VERSION ""

NS_ :

BS_:

BU_: XXX

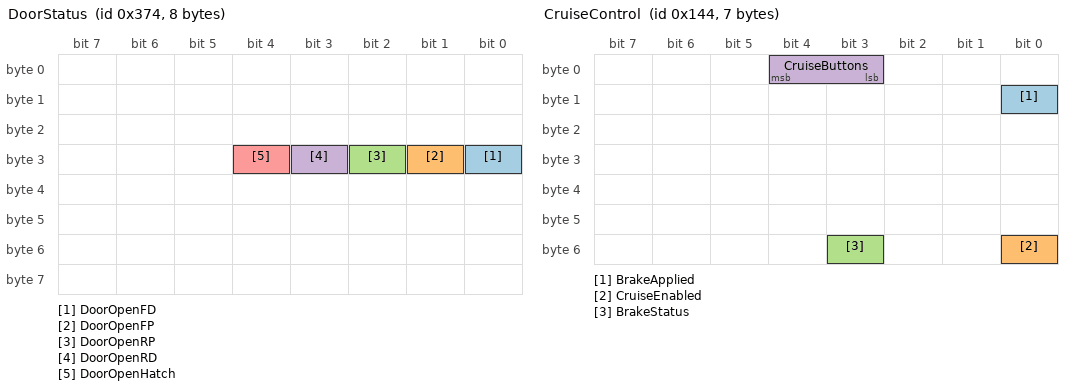
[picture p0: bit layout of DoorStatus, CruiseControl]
BO_ 884 DoorStatus: 8 XXX
 SG_ DoorOpenFD : 24|1@0+ (1,0) [0|1] "" XXX
 SG_ DoorOpenFP : 25|1@0+ (1,0) [0|1] "" XXX
 SG_ DoorOpenRP : 26|1@0+ (1,0) [0|1] "" XXX
 SG_ DoorOpenRD : 27|1@0+ (1,0) [0|1] "" XXX
 SG_ DoorOpenHatch : 28|1@0+ (1,0) [0|1] "" XXX

BO_ 324 CruiseControl: 7 XXX
 SG_ BrakeApplied : 8|1@0+ (1,0) [0|0] "" XXX
 SG_ CruiseEnabled : 48|1@0+ (1,0) [0|0] "" XXX
 SG_ BrakeStatus : 51|1@0+ (1,0) [0|0] "" XXX
 SG_ CruiseButtons : 4|2@0+ (1,0) [0|3] "" XXX

BO_ 320 Throttle: 8 XXX
 SG_ ThrottlePosition : 7|8@0+ (1,0) [0|255] "" XXX

BO_ 209 NEW_MSG_1: 8 XXX
 SG_ BrakePosition : 23|8@0+ (1,0) [0|255] "" XXX

BO_ 2 Steering: 8 XXX
 SG_ SteeringAngle : 7|16@0- (0.1,0) [-500|500] "degree" XXX

BO_ 642 NEW_MSG_2: 8 XXX
 SG_ TurnSignal : 45|2@0+ (1,0) [0|3] "" XXX

VAL_ 324 BrakeApplied 1 "On" 0 "Off" ;
VAL_ 324 CruiseEnabled 1 "On" 0 "Off" ;
VAL_ 324 BrakeStatus 1 "On" 0 "Off" ;
VAL_ 324 CruiseButtons 2 "Set" 1 "Resume" ;

VAL_ 624 TurnSignal 2 "Left" 1 "Right" ;

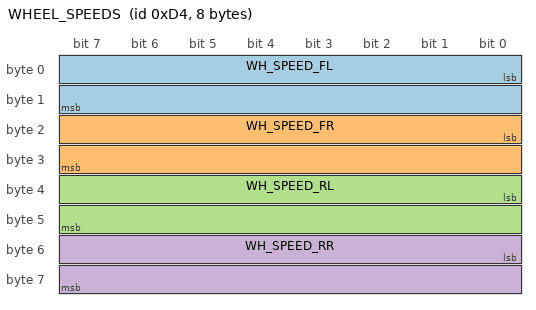
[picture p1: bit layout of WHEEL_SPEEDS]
BO_ 212 WHEEL_SPEEDS: 8 XXX
 SG_ WH_SPEED_FL : 0|16@1- (0.05625,0) [0|65535] "km/h" XXX
 SG_ WH_SPEED_FR : 16|16@1- (0.05625,0) [0|65535] "km/h" XXX
 SG_ WH_SPEED_RL : 32|16@1- (0.05625,0) [0|65535] "km/h" XXX
 SG_ WH_SPEED_RR : 48|16@1- (0.05625,0) [0|65535] "km/h" XXX
